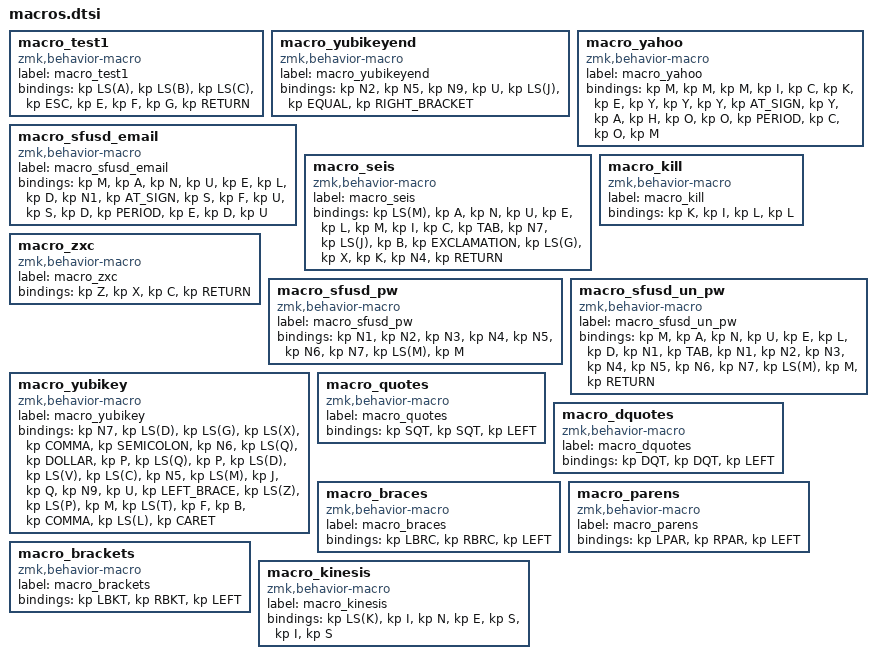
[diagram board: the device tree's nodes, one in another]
macro_test1: macro_test1{
compatible = "zmk,behavior-macro";
label = "macro_test1";
#binding-cells = <0>;
bindings = <&kp LS(A)>, <&kp LS(B)>, <&kp LS(C)>, <&kp ESC>, <&kp E>, <&kp F>, <&kp G>, <&kp RETURN>;
};
macro_yubikeyend: macro_yubikeyend{
compatible = "zmk,behavior-macro";
label = "macro_yubikeyend";
#binding-cells = <0>;
bindings = <&kp N2>, <&kp N5>, <&kp N9>, <&kp U>, <&kp LS(J)>, <&kp EQUAL>, <&kp RIGHT_BRACKET>;
};
macro_yahoo: macro_yahoo{
compatible = "zmk,behavior-macro";
label = "macro_yahoo";
#binding-cells = <0>;
bindings = <&kp M>, <&kp M>, <&kp M>, <&kp I>, <&kp C>, <&kp K>, <&kp E>, <&kp Y>, <&kp Y>, <&kp Y>, <&kp AT_SIGN>, <&kp Y>, <&kp A>, <&kp H>, <&kp O>, <&kp O>, <&kp PERIOD>, <&kp C>, <&kp O>, <&kp M>;
};
macro_sfusd_email: macro_sfusd_email{
compatible = "zmk,behavior-macro";
label = "macro_sfusd_email";
#binding-cells = <0>;
bindings = <&kp M>, <&kp A>, <&kp N>, <&kp U>, <&kp E>, <&kp L>, <&kp D>, <&kp N1>, <&kp AT_SIGN>, <&kp S>, <&kp F>, <&kp U>, <&kp S>, <&kp D>, <&kp PERIOD>, <&kp E>, <&kp D>, <&kp U>;
};
macro_seis: macro_seis{
compatible = "zmk,behavior-macro";
label = "macro_seis";
#binding-cells = <0>;
bindings = <&kp LS(M)>, <&kp A>, <&kp N>, <&kp U>, <&kp E>, <&kp L>, <&kp M>, <&kp I>, <&kp C>, <&kp TAB>, <&kp N7>, <&kp LS(J)>, <&kp B>, <&kp EXCLAMATION>, <&kp LS(G)>, <&kp X>, <&kp K>, <&kp N4>, <&kp RETURN>;
};
macro_kill: macro_kill{
compatible = "zmk,behavior-macro";
label = "macro_kill";
#binding-cells = <0>;
bindings = <&kp K>, <&kp I>, <&kp L>, <&kp L>;
};
macro_zxc: macro_zxc{
compatible = "zmk,behavior-macro";
label = "macro_zxc";
#binding-cells = <0>;
bindings = <&kp Z>, <&kp X>, <&kp C>, <&kp RETURN>;
};
macro_sfusd_pw: macro_sfusd_pw{
compatible = "zmk,behavior-macro";
label = "macro_sfusd_pw";
#binding-cells = <0>;
bindings = <&kp N1>, <&kp N2>, <&kp N3>, <&kp N4>, <&kp N5>, <&kp N6>, <&kp N7>, <&kp LS(M)>, <&kp M>;
};
macro_sfusd_un_pw: macro_sfusd_un_pw{
compatible = "zmk,behavior-macro";
label = "macro_sfusd_un_pw";
#binding-cells = <0>;
bindings = <&kp M>, <&kp A>, <&kp N>, <&kp U>, <&kp E>, <&kp L>, <&kp D>, <&kp N1>, <&kp TAB>, <&kp N1>, <&kp N2>, <&kp N3>, <&kp N4>, <&kp N5>, <&kp N6>, <&kp N7>, <&kp LS(M)>, <&kp M>, <&kp RETURN>;
};
macro_yubikey: macro_yubikey{
compatible = "zmk,behavior-macro";
label = "macro_yubikey";
#binding-cells = <0>;
bindings = <&kp N7>, <&kp LS(D)>, <&kp LS(G)>, <&kp LS(X)>, <&kp COMMA>, <&kp SEMICOLON>, <&kp N6>, <&kp LS(Q)>, <&kp DOLLAR>, <&kp P>, <&kp LS(Q)>, <&kp P>, <&kp LS(D)>, <&kp LS(V)>, <&kp LS(C)>, <&kp N5>, <&kp LS(M)>, <&kp J>, <&kp Q>, <&kp N9>, <&kp U>, <&kp LEFT_BRACE>, <&kp LS(Z)>, <&kp LS(P)>, <&kp M>, <&kp LS(T)>, <&kp F>, <&kp B>, <&kp COMMA>, <&kp LS(L)>, <&kp CARET>;
};
macro_quotes: macro_quotes{
compatible = "zmk,behavior-macro";
label = "macro_quotes";
#binding-cells = <0>;
bindings = <&kp SQT>, <&kp SQT>, <&kp LEFT>;
};
macro_dquotes: macro_dquotes{
compatible = "zmk,behavior-macro";
label = "macro_dquotes";
#binding-cells = <0>;
bindings = <&kp DQT>, <&kp DQT>, <&kp LEFT>;
};
macro_braces: macro_braces{
compatible = "zmk,behavior-macro";
label = "macro_braces";
#binding-cells = <0>;
bindings = <&kp LBRC>, <&kp RBRC>, <&kp LEFT>;
};
macro_parens: macro_parens{
compatible = "zmk,behavior-macro";
label = "macro_parens";
#binding-cells = <0>;
bindings = <&kp LPAR>, <&kp RPAR>, <&kp LEFT>;
};
macro_brackets: macro_brackets{
compatible = "zmk,behavior-macro";
label = "macro_brackets";
#binding-cells = <0>;
bindings = <&kp LBKT>, <&kp RBKT>, <&kp LEFT>;
};
macro_kinesis: macro_kinesis{
compatible = "zmk,behavior-macro";
label = "macro_kinesis";
#binding-cells = <0>;
bindings = <&kp LS(K)>, <&kp I>, <&kp N>, <&kp E>, <&kp S>, <&kp I>, <&kp S>;
};
